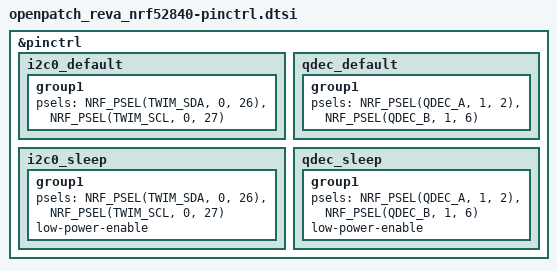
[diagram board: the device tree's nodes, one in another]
/*
 * SPDX-License-Identifier: Apache-2.0
 * Peripheral pin routing for OpenPatch Rev A. Source of truth: electronics/pin-assignment.md
 * (ISP1807 module pad -> nRF52840 port.pin). Plain GPIOs live in openpatch_reva_nrf52840.dts.
 */

&pinctrl {
	/* I2C: TMAG5273 (0x35) only; 4.7k pull-up is on the board */
	i2c0_default: i2c0_default {
		group1 {
			psels = <NRF_PSEL(TWIM_SDA, 0, 26)>,
				<NRF_PSEL(TWIM_SCL, 0, 27)>;
		};
	};

	i2c0_sleep: i2c0_sleep {
		group1 {
			psels = <NRF_PSEL(TWIM_SDA, 0, 26)>,
				<NRF_PSEL(TWIM_SCL, 0, 27)>;
			low-power-enable;
		};
	};

	/* HALL_A / HALL_B: 2x DRV5032 push-pull outputs, counted by QDEC independent of the CPU */
	qdec_default: qdec_default {
		group1 {
			psels = <NRF_PSEL(QDEC_A, 1, 2)>,
				<NRF_PSEL(QDEC_B, 1, 6)>;
		};
	};

	qdec_sleep: qdec_sleep {
		group1 {
			psels = <NRF_PSEL(QDEC_A, 1, 2)>,
				<NRF_PSEL(QDEC_B, 1, 6)>;
			low-power-enable;
		};
	};
};
